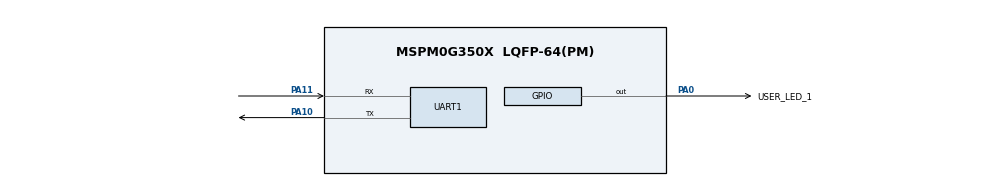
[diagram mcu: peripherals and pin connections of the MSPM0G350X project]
// @cliArgs --device "MSPM0G350X" --package "LQFP-64(PM)" --part "Default"
// @cliArgs --board /ti/boards/LP_MSPM0G3507 --rtos nortos

/**
 * Import the modules used in this configuration.
 */
const UART   = scripting.addModule("/ti/driverlib/UART", {}, false);
const UART1  = UART.addInstance();

const GPIO   = scripting.addModule("/ti/driverlib/GPIO", {}, false);
const GPIO1  = GPIO.addInstance();

const SYSCTL = system.modules["/ti/driverlib/SYSCTL"].$static;

/**
 * Write custom configuration values to the imported modules.
 */
const Board = scripting.addModule("/ti/driverlib/Board", {}, false);
Board.configureUnused = true;

UART1.$name = "UART_0";
UART1.profile = "CONFIG_PROFILE_1";
UART1.peripheral.$assign = "UART0";
UART1.uartClkSrc = "LFCLK";
UART1.ovsRate = "3";
UART1.targetBaudRate = 9600;
UART1.enableInternalLoopback = false;
UART1.enabledInterrupts = ["RX"];
UART1.enableFIFO= false;

UART1.peripheral.rxPin.$assign = "PA11";
UART1.peripheral.txPin.$assign = "PA10";

GPIO1.$name                          = "GPIO_LEDS";
GPIO1.associatedPins.create(2);
GPIO1.associatedPins[0].$name        = "USER_LED_1";
GPIO1.associatedPins[0].assignedPort = "PORTA";
GPIO1.associatedPins[0].initialValue = "SET";
GPIO1.associatedPins[0].assignedPin  = "0";
GPIO1.associatedPins[0].pin.$assign  = "PA0";
GPIO1.associatedPins[1].$name        = "USER_TEST";
GPIO1.associatedPins[1].assignedPort = "PORTA";
GPIO1.associatedPins[1].assignedPin  = "15";
GPIO1.associatedPins[1].initialValue = "SET";


SYSCTL.powerPolicy = "STANDBY0";
SYSCTL.forceDefaultClkConfig = true;
SYSCTL.clockTreeEn  = true;
